# TZ10xx register map
File version: 0.1g
Registers are 32-bit, read-write, reset 0x0 unless marked. A register's access mark holds for its fields unless they carry their own. Offsets are from the block's base; [hi:lo] are bit positions; {n}, {i} and the like mark numbered series; 'fields as' and 'values as' point back to an identical list.

## adcc24
Base 0x40049000
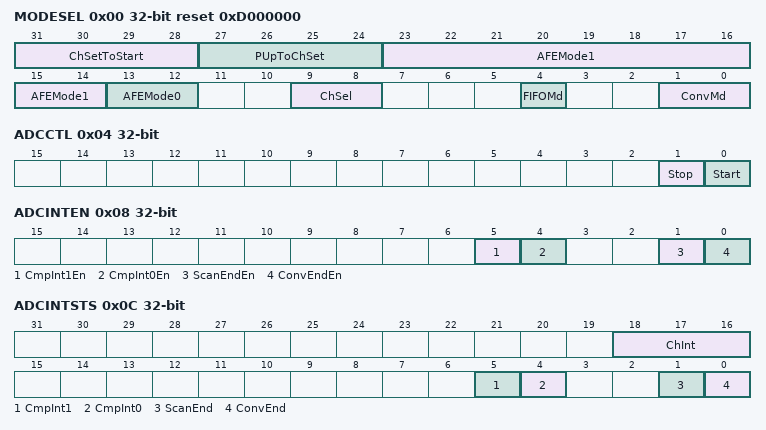
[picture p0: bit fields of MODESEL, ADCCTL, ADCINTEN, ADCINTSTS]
0x00 MODESEL reset 0xD000000 — Mode set register
  [31:28] ChSetToStart — ADC Channel Select to Conversion Start Sets a period between ADC macro channel setting (switching) and start of conversion. The period is the number of cycles given by: (Settings) x reference clock *) Reference clock is 32 divisions of ADC clocks.
  [27:24] PUpToChSet — ADC PowerUp to Channel Set Sets a period between ADC macro power down release and channel set (start of conversion if ChSetToStart setting is "0") The period is the number of cycles given by: (Settings + 2) x reference clock *) Reference clock is 32 divisions of ADC clocks.
  [23:14] AFEMode1 — AFE mode selection Sets parameters for configurable AFE. Connected to AFE configuration signal: CNT MODE[1:2] Please see "Configurable AFE" section for detail. *) These bits are used only when the conversion mode is Single.
  [13:12] AFEMode0 — AFE mode setting Sets parameters for configurable AFE. Connected to AFE configuration signal: CNT MODE[1:0] Please see "Configurable AFE" section for detail.
  [9:8] ChSel — Channel selection Sets the channel number that the AD conversion is made. Used only when conversion mode is Single 00: Ch0 01: Ch1 10: Ch2 11: Reserved
  [4] FIFOMd — FIFO mode Sets the method of storing conversion data in FIFO. 0: Stream Discards the oldest data and stores the latest data in FIFO when FIFO is full. 1: FIFO stop Retains data in FIFO and discards the latest data when FIFO is full.
  [1:0] ConvMd — Conversion mode Sets ADC conversion modes. 00: Single Performs conversion of a channel specified by ChSel. 01: One-time scan Sequentially performs conversion for channels enabled by each channel set register. Comes to a stop after one round of conversions. 10: Cyclic scan Sequentially performs conversion for channels enabled by each channel set register. Repeats conversion operation until a stop instruction is issued by a control register. 11: Reserved
0x04 ADCCTL — AD conversion control register
  [1] Stop — Stop conversion Forcibly stops ADC conversion operation. [For read operation] 0: ADC in operation or going to stop 1: ADC conversion is stopped [For write operation] 0: - 1: Starts AD conversion stop oepration Writing "1" to this bit can stop AD conversion. After conversion operation being executed has been completed, ADC comes to a stop and this bit is returned to "0". When ADC conversion is being stopped (Start bit is "0"), "1" cannot be written to this bit. "0" cannot be written to this bit (Even if "0" is written, stop operation cannot be cancelled.)
  [0] Start — Start of conversion Starts ADC conversion [For read operation] 0: ADC conversion is stopped 1: ADC conversion in operation [For write operation] 0: - 1: Starts AD conversion Writing "1" to this bit starts AD conversion operation. In the Single mode and One-Time Scan mode, this bit is automatically returned to "0" when all of conversion operations have been completed. Writing "1" to the Stop bit during conversion operation causes the bit to return to "0" after conversion operation being executed has been completed. "0" cannot be written to this bit (Even if "0" is written, ADC conversion operation cannot be stopped.)
0x08 ADCINTEN — AD conversion interrupt control register
  [5] CmpInt1En — Converted value comparison 1 interrupt 0: Disable 1: Enable
  [4] CmpInt0En — Converted value comparison 1 interrupt 0: Disable 1: Enable
  [1] ScanEndEn — Scan operation termination interrupt 0: Disable 1: Enable
  [0] ConvEndEn — Conversion termination interrupt 0: Disable 1: Enable
0x0C ADCINTSTS — AD conversion interrupt status register
  [18:16] ChInt ro — Channel interrupt Indicates interrupt occurrence status in each of Ch 0 to 3. 0: No interrupt occurred 1: Interrupt occurred Details of interrupt factors can be checked by the interrupt status register for each channel.
  [5] CmpInt1 — Converted value comparison 1 interrupt [For read] 0: No interrupt occurred 1: Interrupt occurred [For write] 0: - 1: Clear interrupt
  [4] CmpInt0 — Converted value comparison 0 interrupt [For read] 0: No interrupt occurred 1: Interrupt occurred [For write] 0: - 1: Clear interrupt
  [1] ScanEnd — Scan operation termination interrupt [For read] 0: No interrupt occurred 1: Interrupt occurred [For write] 0: - 1: Clear interrupt
  [0] ConvEnd — Conversion termination interrupt [For read] 0: No interrupt occurred 1: Interrupt occurred [For write] 0: - 1: Clear interrupt
0x10 SPLT_CTRCTL — Sampling timing generation counter control register
  [6:4] SrcSel — Source clock selection for sampling timing generation counter 000: ADC clock 001: 4 divisions of ADC clock 010: 16 divisions of ADC clock 011: 64 divisions of ADC clock 100: RTC clock Other than those above: Settings prohibited
0x14 SPLT_PER — Sampling period setting register
  [15:0] Period — Specifies the period of sampling timing signal Set the number of clock cycles of sampling timing generation counter. Setting of "0x0000" is prohibited. Set values in the range from "0x0001" to "0xffff".
0x18 SPLT_WAVCFG — Sampling timing signal waveform setting register
  [15:0] CycToRise — Specfies the time to rise of sampling timing signal Set the number of clock cycles of sampling timing generation counter. Set values smaller than [SPLT_PER].
0x1C SPLT_SYNC_WAVCFG — Sampling timing synchronous signal waveform setting register
  [15:0] CycToRise — Specfies the time to rise of sampling timing synchronous signal Set the number of clock cycles of sampling timing generation counter. Set values smaller than [SPLT_PER].
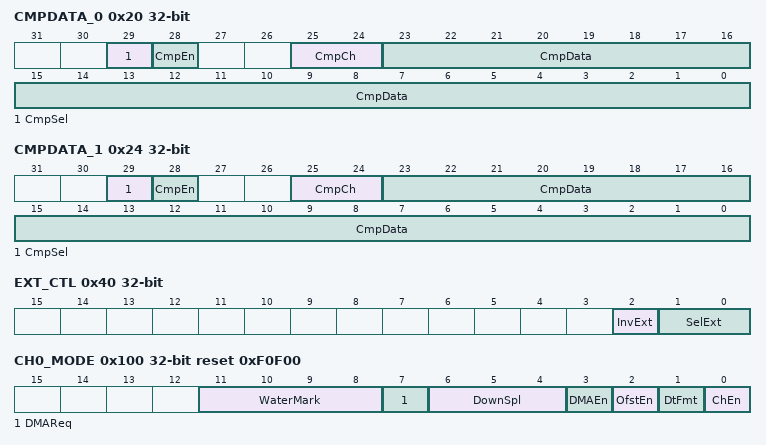
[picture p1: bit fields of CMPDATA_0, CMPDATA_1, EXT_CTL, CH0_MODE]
0x20 CMPDATA_0 — Compare data setting register 0
  [29] CmpSel — Compare mode select 0: An interrupt occurs when converted values is larger than compare data. 1: An interrupt occurs when converted values is smaller than converted values
  [28] CmpEn — Compare enable 0: Converted values not compared 1: Converted values compared
  [25:24] CmpCh — Compare channel select Selects a channel where converted values are compared 00: Ch0 01: Ch1 10: Ch2 11: Reserved
  [23:0] CmpData — Compare data Converted values to be stored in FIFO and the value of this register field are compared, and an interrupt signal is generated according to the results of comparison as to which is greater or smaller. Comparison as to which is greater or smaller is specified by the CmpSel bit.
0x24 CMPDATA_1 — Compare data setting register 1
  [29] CmpSel — Same as CMPDATA_0
  [28] CmpEn — Same as CMPDATA_0
  [25:24] CmpCh — Same as CMPDATA_0
  [23:0] CmpData — Same as CMPDATA_0
0x40 EXT_CTL — External output signal control register
  [2] InvExt — External output signal inversion select 0: Not inverted 1: Inverted *) Invert/Not invert process is performed on data selected by SelExt
  [1:0] SelExt — External output signal data selection 00: "0" is always output 01: "1" is always output 10/11: Sampling timing synchronous signals are output
0x100 CH0_MODE reset 0xF0F00 — Channel 0 mode setting register
  [11:8] WaterMark — Watermark interrupt level count Selects the number of FIFO steps where Watermark interrupt is generated 000: 1 step 001: 2 steps 010: 3 steps 011: 4 steps ... 110: 15 steps 111: 16 steps
  [7] DMAReq — DMA request status [For read] 0: No DMA request 1: DMA request asserted [For write] 0: - 1: Cancell DMA request
  [6:4] DownSpl — Down Sampling 000: No down sampling (sampling done every time) 001: One sampling in two times 010: One sampling in three times ... 110: One sampling in seven times 111: One sampling in eight times
  [3] DMAEn — DMA transfer request enable 0: Disable 1: Enable
  [2] OfstEn — Offset for conversion data enable 0: Disable 1: Enable
  [1] DtFmt — Conversion data format Selects formats of data to be stored in FIFO 0: Unsigned integer 1: Signed integer
  [0] ChEn — Channel enable Determines whether an analog input of this channel is subjected to AD conversion. Enabled only in the One-Time and Cyclic Scan modes. In Single mode, the channel set to [MODESEL].ChSel are selected regardless of settings of this bit. 0: Disable 1: Enable
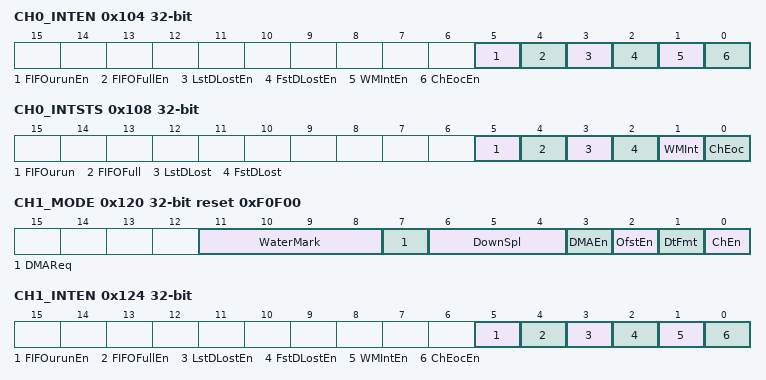
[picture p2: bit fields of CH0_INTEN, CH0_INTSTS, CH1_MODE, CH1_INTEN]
0x104 CH0_INTEN — Channel 0 interrupt control register
  [5] FIFOurunEn — FIFO underrun interrupt 0: Disable 1: Enable
  [4] FIFOFullEn — FIFO full interrupt 0: Disable 1: Enable
  [3] LstDLostEn — Last data lost interrupt 0: Disable 1: Enable
  [2] FstDLostEn — 1st data lost interrupt 0: Disable 1: Enable
  [1] WMIntEn — Watermark interrupt 0: Disable 1: Enable
  [0] ChEocEn — End of Conversion interrupt 0: Disable 1: Enable
0x108 CH0_INTSTS — Channel 0 interrupt status register
  [5] FIFOurun — FIFO underrun interrupt [For read] 0: No interrupt occurred 1: Interrupt occurred [For write] 0: - 1: Clear interrupt
  [4] FIFOFull — FIFO full interrupt [For read] 0: No interrupt occurred 1: Interrupt occurred [For write] 0: - 1: Clear interrupt
  [3] LstDLost — Last data lost interrupt [For read] 0: No interrupt occurred 1: Interrupt occurred [For write] 0: - 1: Clear interrupt
  [2] FstDLost — 1st data lost interrupt [For read] 0: No interrupt occurred 1: Interrupt occurred [For write] 0: - 1: Clear interrupt
  [1] WMInt — Watermark interrupt [For read] 0: No interrupt occurred 1: Interrupt occurred [For write] 0: - 1: Clear interrupt
  [0] ChEoc — Conversion completion interrupt [For read] 0: No interrupt occurred 1: Interrupt occurred [For write] 0: - 1: Clear interrupt
0x10C CH0_OFFSET — Channel 0 conversion data offset
  [7:0] Offset — Offset data for adjusting conversion data If offset for conversion data is enabled, conversrion result is added with this register's value and then sotred to FIFO. MSB of this register is a sign bit (i.e. calculation with conversion result is done after sign extention). If arithmetic result is larger tha the upper limit or smaller than lower limits of the conversion range, limit values are stored in FIFO.
0x110 CH0_FIFOSTS ro — Channel 0 FIFO status
  [4:0] DataNum — Number of pieces of data in FIFO 0 to 16 word(s)
0x118 CH0_AFEMODE — Channel 0 AFE mode setting register
  [11:2] Mode — AFE mode setting Sets parameters for configurable AFE. Connected to AFE configuration signal: CNT MODE[11:2] Please see "Configurable AFE" section for detail.
0x120 CH1_MODE reset 0xF0F00 — Channel 1 mode setting register
  [11:8] WaterMark, [7] DMAReq, [6:4] DownSpl, [3] DMAEn, [2] OfstEn, [1] DtFmt, [0] ChEn
0x124 CH1_INTEN — Channel 1 interrupt control register
  [5] FIFOurunEn, [4] FIFOFullEn, [3] LstDLostEn, [2] FstDLostEn, [1] WMIntEn, [0] ChEocEn
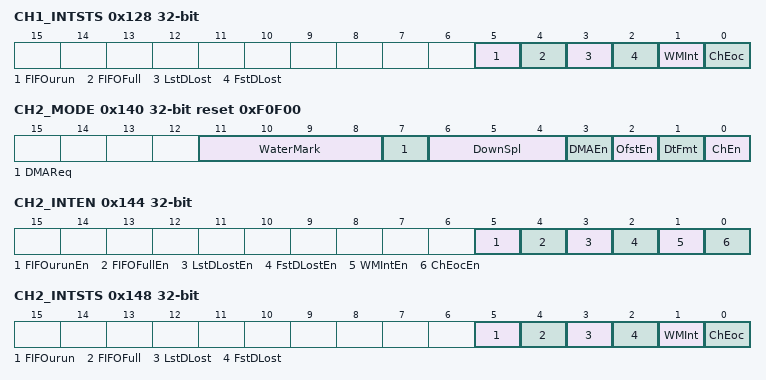
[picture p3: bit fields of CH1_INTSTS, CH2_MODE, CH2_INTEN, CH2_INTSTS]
0x128 CH1_INTSTS — Channel 1 interrupt status register
  [5] FIFOurun, [4] FIFOFull, [3] LstDLost, [2] FstDLost, [1] WMInt, [0] ChEoc
0x12C CH1_OFFSET — Channel 1 conversion data offset
  [7:0] Offset
0x130 CH1_FIFOSTS ro — Channel 1 FIFO status
  [4:0] DataNum
0x138 CH1_AFEMODE — Channel 1 AFE mode setting register
  [11:2] Mode
0x140 CH2_MODE reset 0xF0F00 — Channel 2 mode setting register
  fields as CH1_MODE
0x144 CH2_INTEN — Channel 2 interrupt control register
  fields as CH1_INTEN
0x148 CH2_INTSTS — Channel 2 interrupt status register
  fields as CH1_INTSTS
0x14C CH2_OFFSET — Channel 2 conversion data offset
  [7:0] Offset
0x150 CH2_FIFOSTS ro — Channel 2 FIFO status
  [4:0] DataNum
0x158 CH2_AFEMODE — Channel 2 AFE mode setting register
  [11:2] Mode
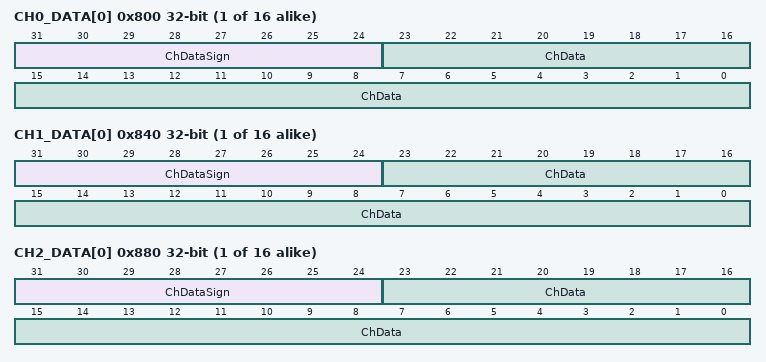
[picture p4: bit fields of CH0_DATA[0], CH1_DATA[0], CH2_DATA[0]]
{0x800+4i} CH0_DATA[{i}] (i=0..15) ro — Channel 0 conversion result data register *) Though there is a 64-byte region ranging 0x800 to 0x83f, each address is allocated to the same FIFO output. Read should be done with 32-bit access. 8-bit/16bit read makes the FIFO to next level.
  [31:24] ChDataSign
  [23:0] ChData — CH0 conversion data FIFO
{0x840+4i} CH1_DATA[{i}] (i=0..15) ro — Channel 1 conversion result data register *) Though there is a 64-byte region ranging 0x840 to 0x87f, each address is allocated to the same FIFO output. Read should be done with 32-bit access. 8-bit/16bit read makes the FIFO to next level.
  [31:24] ChDataSign
  [23:0] ChData — CH1 conversion data FIFO
{0x880+4i} CH2_DATA[{i}] (i=0..15) ro — Channel 2 conversion result data register *) Though there is a 64-byte region ranging 0x880 to 0x8bf, each address is allocated to the same FIFO output. Read should be done with 32-bit access. 8-bit/16bit read makes the FIFO to next level.
  [31:24] ChDataSign
  [23:0] ChData — CH2 conversion data FIFO
